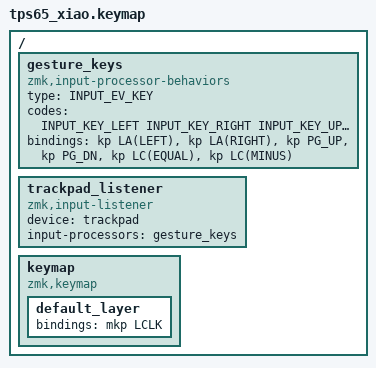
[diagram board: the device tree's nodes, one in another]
#include <behaviors.dtsi>
#include <input/processors.dtsi>
#include <dt-bindings/zmk/keys.h>
#include <dt-bindings/zmk/pointing.h>
#include <zephyr/dt-bindings/input/input-event-codes.h>

/ {
    /* Gesture keys from the driver -> shortcuts (test mapping, Linux/browser friendly). */
    gesture_keys: gesture_keys {
        compatible = "zmk,input-processor-behaviors";
        #input-processor-cells = <0>;
        type = <INPUT_EV_KEY>;
        codes = <INPUT_KEY_LEFT INPUT_KEY_RIGHT INPUT_KEY_UP INPUT_KEY_DOWN
                 INPUT_KEY_KPPLUS INPUT_KEY_KPMINUS>;
        bindings = <&kp LA(LEFT) &kp LA(RIGHT) &kp PG_UP &kp PG_DN
                    &kp LC(EQUAL) &kp LC(MINUS)>;
    };

    trackpad_listener {
        compatible = "zmk,input-listener";
        device = <&trackpad>;
        input-processors = <&gesture_keys>;
    };

    keymap {
        compatible = "zmk,keymap";
        default_layer {
            bindings = <&mkp LCLK>;
        };
    };
};
